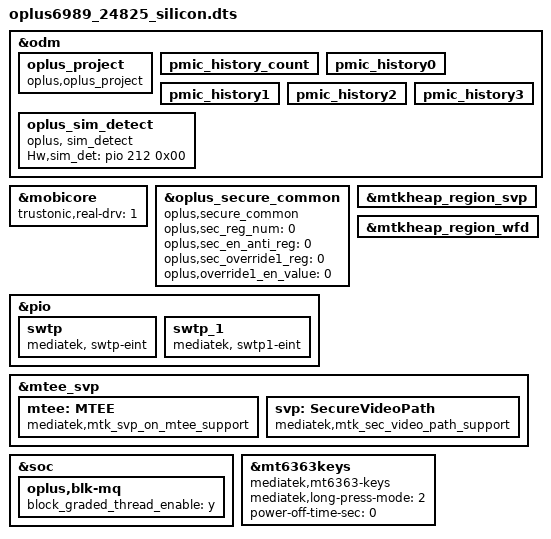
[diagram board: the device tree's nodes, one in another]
// SPDX-License-Identifier: (GPL-2.0 OR MIT)
/*
 * Copyright (C) 2022 MediaTek Inc.
 */
#include "k6989v2_64.dts"
/* Add for DX-4 ppb device-tree */
#include "mediatek/oplus_ppb_24825.dtsi"
/* #endif */

/* Add for Subaru(24825) fingerprint device-tree */
/* #ifdef CONFIG_UFF_FINGERPRINT */
#include "mediatek/oplus_uff_24825.dtsi"
/* #endif CONFIG_UFF_FINGERPRINT */

//#ifdef OPLUS_FEATURE_SENSOR
#include "mediatek/oplus_sensor_24825.dtsi"
//#endif

/* #ifdef OPLUS_FEATURE_CHG_BASIC */
#include "mediatek/oplus_charge_24825_silicon.dtsi"
/* #endif OPLUS_FEATURE_CHG_BASIC */

/* Add for DX-4 ppb device-tree */
#include "mediatek/oplus_ppb_24825.dtsi"
/* #endif */

&odm {
    /*OPLUS_FEATURE_OEM_OCDT oppo project start */
	oplus_project:oplus_project {
		compatible = "oplus,oplus_project";
	};

	pmic_history_count:pmic_history_count {
 	};
 	pmic_history0:pmic_history0 {
 	};
 	pmic_history1:pmic_history1 {
 	};
 	pmic_history2:pmic_history2 {
 	};
 	pmic_history3:pmic_history3 {
 	};
};

/*
 * Trustonic Mobilecore real driver
 */
&mobicore{
        trustonic,real-drv = <1>;
};

&oplus_secure_common {
    compatible = "oplus,secure_common";
    oplus,sec_reg_num = <0>;
    oplus,sec_en_anti_reg = <0>;
    oplus,sec_override1_reg = <0>;
    oplus,override1_en_value = <0>;
};

&pio {
	//#ifdef OPLUS_VENDOR_SWTP
	swtp: swtp {
		compatible = "mediatek, swtp-eint";
	};
	 swtp_1: swtp_1 {
        compatible = "mediatek, swtp1-eint";
    };
	//#endif  /*OPLUS_VENDOR_SWTP*/
};

&odm {
/* Add for sim detect */
    oplus_sim_detect {
        compatible = "oplus, sim_detect";
        Hw,sim_det = <&pio 212 0x00>;
    };
};
&mtkheap_region_svp {
    status = "ok";
};
&mtkheap_region_wfd {
    status = "ok";
};
&mtee_svp {
    mtee: MTEE {
        compatible = "mediatek,mtk_svp_on_mtee_support";
    };

    svp: SecureVideoPath {
        compatible = "mediatek,mtk_sec_video_path_support";
    };
};

&soc {
	oplus,blk-mq {
		//for blk-mq.c block_graded_thread_enable
		block_graded_thread_enable = "y";
	};
};

//Add 6363 change
&mt6363keys {
	compatible = "mediatek,mt6363-keys";
	mediatek,long-press-mode = <2>;
	power-off-time-sec = <0>;
};

#include "oplus_tp_24825.dtsi"
#include <oplus6989_24825/cust.dtsi>
#include "mediatek/nfc/mt6989_24825_thn31s.dtsi"
#include "mediatek/cust_mt6989_24825_audio.dtsi"
#include "mediatek/cust_mt6989_subaru_camera_v4l2.dtsi"
#include "mediatek/oplus_misc_24825.dtsi"
#include "oplus_connectivity_24825.dtsi"
#include "mediatek/display/oplus6989_24825_display.dtsi"
#include "mediatek/cust_mt6989_thermal.dtsi"
/*End of this file, DO NOT ADD ANYTHING HERE*/
